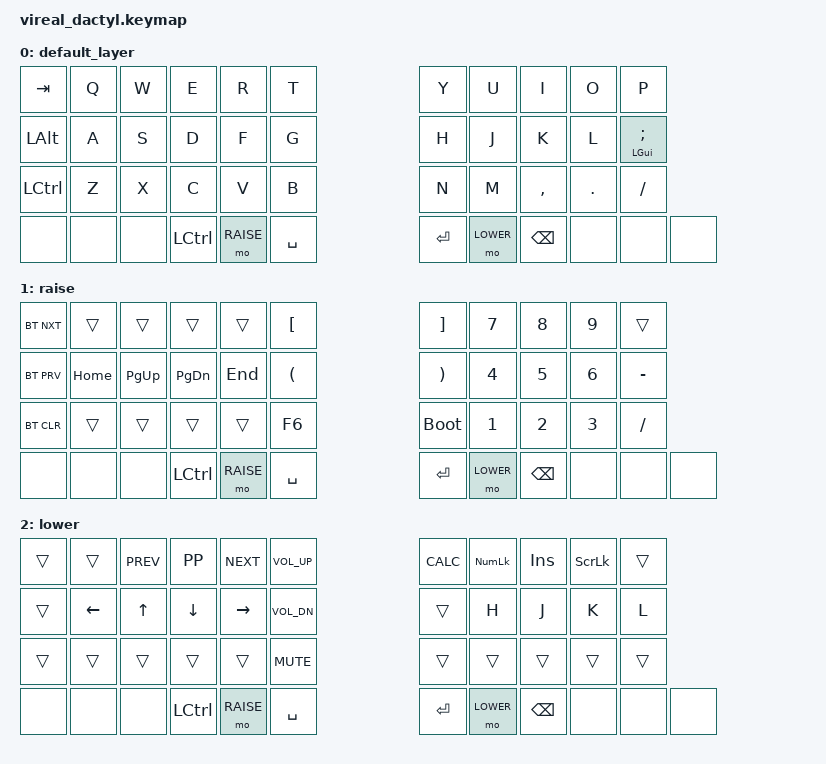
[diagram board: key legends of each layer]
#include <behaviors.dtsi>
#include <dt-bindings/zmk/keys.h>
#include <dt-bindings/zmk/bt.h>

#define DEFAULT 0
#define RAISE   1
#define LOWER   2

/ {
    k    keymap {
        compatible = "zmk,keymap";

        default_layer {
            bindings = 
                &kp TAB    &kp Q      &kp W     &kp E      &kp R      &kp T                           &kp Y      &kp U      &kp I      &kp O      &kp P        
                &kp LALT   &kp A      &kp S     &kp D      &kp F      &kp G                           &kp H      &kp J      &kp K      &kp L      &mt LGUI SEMI
                &kp LCTRL  &kp Z      &kp X     &kp C      &kp V      &kp B                           &kp N      &kp M      &kp COMMA  &kp DOT    &kp FSLH     
                &none      &none      &none     &kp LCTRL  &mo RAISE  &kp SPACE                       &kp ENTER  &mo LOWER  &kp BSPC   &none      &none      &none
            >;
        };

        raise {
            bindings = 
                &bt BT_NXT   &trans     &trans    &trans     &trans     &kp LBKT                        &kp RBKT      &kp 7      &kp 8      &kp 9      &trans
                &bt BT_PRV   &kp HOME   &kp PG_UP &kp PG_DN  &kp END    &kp LPAR                        &kp RPAR      &kp 4      &kp 5      &kp 6      &kp MINUS
                &bt BT_CLR   &trans     &trans    &trans     &trans     &kp F6                          &bootloader   &kp 1      &kp 2      &kp 3      &kp FSLH
                &none        &none      &none     &kp LCTRL  &mo RAISE  &kp SPACE                       &kp ENTER     &mo LOWER  &kp BSPC   &none      &none      &none
            >;
        };

        lower {
            bindings = 
                &trans     &trans     &kp K_PREV &kp K_PP   &kp K_NEXT &kp C_VOL_UP                    &kp K_CALC &kp KP_NUM &kp INS    &kp SLCK   &trans
                &trans     &kp LEFT   &kp UP     &kp DOWN   &kp RIGHT  &kp C_VOL_DN                    &trans     &kp H      &kp J      &kp K      &kp L
                &trans     &trans     &trans     &trans     &trans     &kp C_MUTE                      &trans     &trans     &trans     &trans     &trans
                &none      &none      &none      &kp LCTRL  &mo RAISE  &kp SPACE                       &kp ENTER  &mo LOWER  &kp BSPC   &none      &none      &none
            >;
        };
   };
};
